# LPC51U68 register map
Vendor: nxp.com; File version: 1.0
CPU: CM0PLUS r0p0, little endian, no MPU, no FPU, VTOR, 2 interrupt priority bits
Registers are 32-bit, read-write, reset 0x0 unless marked. A register's access mark holds for its fields unless they carry their own. Offsets are from the block's base; [hi:lo] are bit positions; {n}, {i} and the like mark numbered series.

## UTICK0 — LPC51u68 Micro-tick Timer (UTICK)
Base 0x4000E000
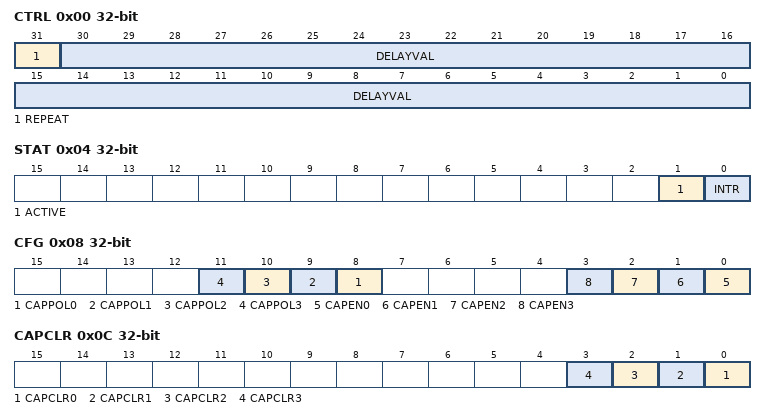
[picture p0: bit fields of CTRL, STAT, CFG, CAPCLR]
0x00 CTRL — Control register.
  [31] REPEAT — Repeat delay. 0 = One-time delay. 1 = Delay repeats continuously.
  [30:0] DELAYVAL — Tick interval value. The delay will be equal to DELAYVAL + 1 periods of the timer clock. The minimum usable value is 1, for a delay of 2 timer clocks. A value of 0 stops the timer.
0x04 STAT — Status register.
  [1] ACTIVE — Active flag. 0 = The Micro-Tick Timer is stopped. 1 = The Micro-Tick Timer is currently active.
  [0] INTR — Interrupt flag. 0 = No interrupt is pending. 1 = An interrupt is pending. A write of any value to this register clears this flag.
0x08 CFG — Capture configuration register.
  [n+8] CAPPOL{n} (n=0..3) — Capture Polarity {n}. 0 = Positive edge capture, 1 = Negative edge capture.
  [n] CAPEN{n} (n=0..3) — Enable Capture {n}. 1 = Enabled, 0 = Disabled.
0x0C CAPCLR wo reset not defined — Capture clear register.
  [n] CAPCLR{n} (n=0..3) — Clear capture {n}. Writing 1 to this bit clears the CAP{n} register value.
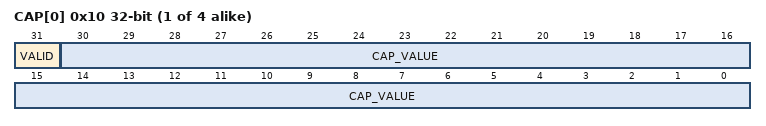
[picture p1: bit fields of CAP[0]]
{0x10+4i} CAP[{i}] (i=0..3) ro — Capture register .
  [31] VALID — Capture Valid. When 1, a value has been captured based on a transition of the related UTICK_CAPn pin. Cleared by writing to the related bit in the CAPCLR register.
  [30:0] CAP_VALUE — Capture value for the related capture event (UTICK_CAPn. Note: the value is 1 lower than the actual value of the Micro-tick Timer at the moment of the capture event.

## FMC — LPC51u68 Flash signature generator
Base 0x40034000
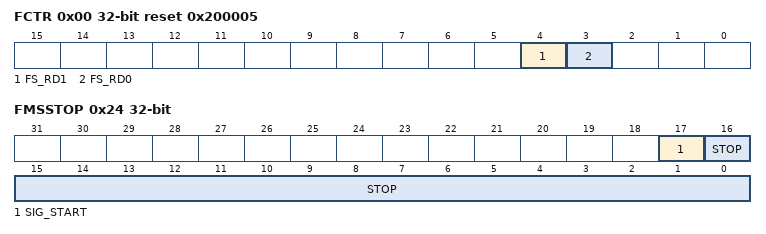
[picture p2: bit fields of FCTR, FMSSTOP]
0x00 FCTR reset 0x200005 — Control register
  [4] FS_RD1 — Value must be 1 for signature generation.
  [3] FS_RD0 — Value must be 0 for signature generation.
0x10 FBWST reset 0xC005 — Wait state register
  [7:0] WAITSTATES — Wait states for signature generation.
0x20 FMSSTART — Signature start address register
  [16:0] START — Signature generation start address (corresponds to AHB byte address bits[20:4]).
0x24 FMSSTOP — Signature stop-address register
  [17] SIG_START — When this bit is written to 1, signature generation starts.
  [16:0] STOP — Stop address for signature generation (the word specified by STOP is included in the address range).
{0x2C+4i} FMSW[{i}] (i=0..3) ro — Words of 128-bit signature word
  [31:0] SW — Words of 128-bit signature (bits).
0xFE0 FMSTAT ro — Signature generation status register
  [2] SIG_DONE — When 1, a previously started signature generation has completed.
0xFE8 FMSTATCLR wo — Signature generation status clear register
  [2] SIG_DONE_CLR — Writing a 1 to this bits clears the signature generation completion flag (SIG_DONE) in the FMSTAT register.

## ASYNC_SYSCON — LPC51u68 Asynchronous system configuration (ASYNC_SYSCON)
Base 0x40040000
0x00 ASYNCPRESETCTRL — Async peripheral reset control
  [13] CTIMER3 — Standard counter/timer CTIMER3 reset control. 0 = Clear reset to this function. 1 = Assert reset to this function.
0x04 ASYNCPRESETCTRLSET wo reset not defined — Set bits in ASYNCPRESETCTRL
  [31:0] ARST_SET — Writing ones to this register sets the corresponding bit or bits in the ASYNCPRESETCTRL register, if they are implemented. Bits that do not correspond to defined bits in ASYNCPRESETCTRL are reserved and only zeroes should be written to them.
0x08 ASYNCPRESETCTRLCLR wo reset not defined — Clear bits in ASYNCPRESETCTRL
  [31:0] ARST_CLR — Writing ones to this register clears the corresponding bit or bits in the ASYNCPRESETCTRL register, if they are implemented. Bits that do not correspond to defined bits in ASYNCPRESETCTRL are reserved and only zeroes should be written to them.
0x10 ASYNCAPBCLKCTRL — Async peripheral clock control
  [13] CTIMER3 — Controls the clock for CTIMER3. 0 = Disable; 1 = Enable.
0x14 ASYNCAPBCLKCTRLSET wo reset not defined — Set bits in ASYNCAPBCLKCTRL
  [31:0] ACLK_SET — Writing ones to this register sets the corresponding bit or bits in the ASYNCAPBCLKCTRL register, if they are implemented. Bits that do not correspond to defined bits in ASYNCPRESETCTRL are reserved and only zeroes should be written to them.
0x18 ASYNCAPBCLKCTRLCLR wo reset not defined — Clear bits in ASYNCAPBCLKCTRL
  [31:0] ACLK_CLR — Writing ones to this register clears the corresponding bit or bits in the ASYNCAPBCLKCTRL register, if they are implemented. Bits that do not correspond to defined bits in ASYNCAPBCLKCTRL are reserved and only zeroes should be written to them.
0x20 ASYNCAPBCLKSELA — Async APB clock source select A
  [1:0] SEL — Clock source for asynchronous clock source selector A
    0=MAIN_CLOCK; 1=FRO_12_MHZ

## FLEXCOMM0 — LPC51u68 Flexcomm serial communication
Base 0x40086000
Same registers: FLEXCOMM1 0x40087000, FLEXCOMM2 0x40088000, FLEXCOMM3 0x40089000, FLEXCOMM4 0x4008A000, FLEXCOMM5 0x40096000, FLEXCOMM6 0x40097000, FLEXCOMM7 0x40098000
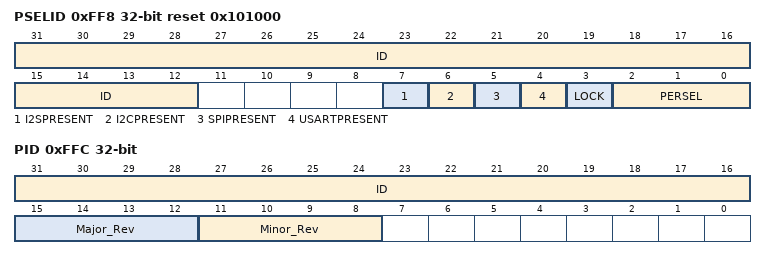
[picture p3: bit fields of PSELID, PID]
0xFF8 PSELID reset 0x101000 — Peripheral Select and Flexcomm ID register.
  [31:12] ID ro — Flexcomm ID.
  [7] I2SPRESENT ro — I 2S present indicator. This field is Read-only.
    0=NOT_PRESENT (This Flexcomm does not include the I2S function.); 1=PRESENT (This Flexcomm includes the I2S function.)
  [6] I2CPRESENT ro — I2C present indicator. This field is Read-only.
    0=NOT_PRESENT (This Flexcomm does not include the I2C function.); 1=PRESENT (This Flexcomm includes the I2C function.)
  [5] SPIPRESENT ro — SPI present indicator. This field is Read-only.
    0=NOT_PRESENT (This Flexcomm does not include the SPI function.); 1=PRESENT (This Flexcomm includes the SPI function.)
  [4] USARTPRESENT ro — USART present indicator. This field is Read-only.
    0=NOT_PRESENT (This Flexcomm does not include the USART function.); 1=PRESENT (This Flexcomm includes the USART function.)
  [3] LOCK — Lock the peripheral select. This field is writable by software.
    0=UNLOCKED (Peripheral select can be changed by software.); 1=LOCKED (Peripheral select is locked and cannot be changed until this Flexcomm or the entire device is reset.)
  [2:0] PERSEL — Peripheral Select. This field is writable by software.
    0=NO_PERIPH_SELECTED (No peripheral selected.); 1=USART (USART function selected.); 2=SPI (SPI function selected.); 3=I2C (I2C function selected.); 4=I2S_TRANSMIT (I2S transmit function selected.); 5=I2S_RECEIVE (I2S receive function selected.)
0xFFC PID ro — Peripheral identification register.
  [31:16] ID — Module identifier for the selected function.
  [15:12] Major_Rev — Major revision of module implementation.
  [11:8] Minor_Rev — Minor revision of module implementation.

## CRC_ENGINE — LPC51u68 CRC engine
Base 0x40095000
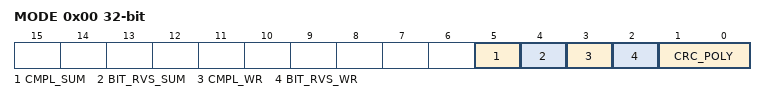
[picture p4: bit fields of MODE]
0x00 MODE — CRC mode register
  [5] CMPL_SUM — CRC sum complement: 1 = 1's complement for CRC_SUM 0 = No 1's complement for CRC_SUM
  [4] BIT_RVS_SUM — CRC sum bit order: 1 = Bit order reverse for CRC_SUM 0 = No bit order reverse for CRC_SUM
  [3] CMPL_WR — Data complement: 1 = 1's complement for CRC_WR_DATA 0 = No 1's complement for CRC_WR_DATA
  [2] BIT_RVS_WR — Data bit order: 1 = Bit order reverse for CRC_WR_DATA (per byte) 0 = No bit order reverse for CRC_WR_DATA (per byte)
  [1:0] CRC_POLY — CRC polynomial: 1X = CRC-32 polynomial 01 = CRC-16 polynomial 00 = CRC-CCITT polynomial
0x04 SEED reset 0xFFFF — CRC seed register
  [31:0] CRC_SEED — A write access to this register will load CRC seed value to CRC_SUM register with selected bit order and 1's complement pre-processes. A write access to this register will overrule the CRC calculation in progresses.
0x08 SUM ro reset 0xFFFF (SUM_WR_DATA view) — CRC checksum register
  [31:0] CRC_SUM — The most recent CRC sum can be read through this register with selected bit order and 1's complement post-processes.
0x08 WR_DATA wo reset not defined (SUM_WR_DATA view) — CRC data register
  [31:0] CRC_WR_DATA — Data written to this register will be taken to perform CRC calculation with selected bit order and 1's complement pre-process. Any write size 8, 16 or 32-bit are allowed and accept back-to-back transactions.
